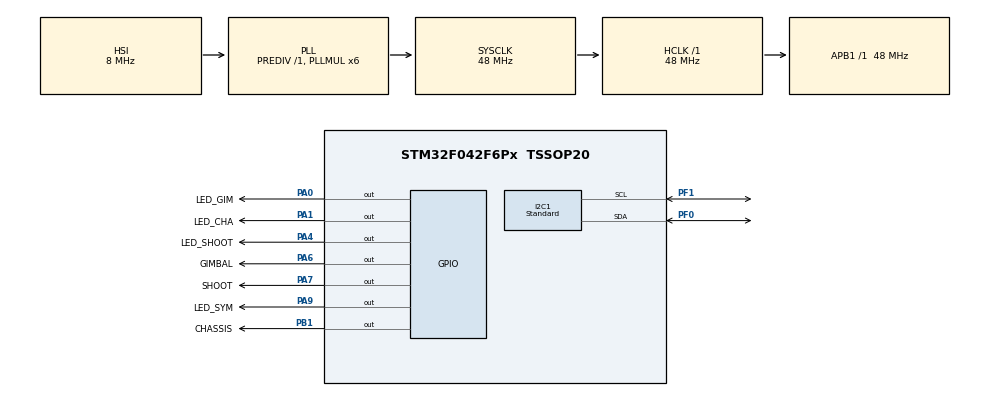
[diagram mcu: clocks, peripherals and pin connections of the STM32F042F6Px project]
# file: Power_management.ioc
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FREERTOS.Tasks01=StartTasks,0,128,StartAllTasks,Default,NULL,Dynamic,NULL,NULL
I2C1.I2C_Speed_Mode=I2C_Standard
I2C1.Timing=0x00201D2B
Mcu.Family=STM32F0
Mcu.Name=STM32F042F6Px
Mcu.Package=TSSOP20
NVIC.I2C1_IRQn=true\:3\:0\:false\:false\:true\:true\:true\:true\:true
NVIC.TIM17_IRQn=true\:3\:0\:false\:false\:true\:false\:false\:true\:true
NVIC.TimeBase=TIM17_IRQn
NVIC.TimeBaseIP=TIM17
PA0.GPIO_Label=LED_GIM
PA0.GPIO_PuPd=GPIO_NOPULL
PA0.PinState=GPIO_PIN_SET
PA0.Signal=GPIO_Output
PA1.GPIO_Label=LED_CHA
PA1.GPIO_PuPd=GPIO_NOPULL
PA1.PinState=GPIO_PIN_SET
PA1.Signal=GPIO_Output
PA13.Mode=Serial_Wire
PA13.Signal=SYS_SWDIO
PA14.Mode=Serial_Wire
PA14.Signal=SYS_SWCLK
PA4.GPIO_Label=LED_SHOOT
PA4.GPIO_PuPd=GPIO_NOPULL
PA4.PinState=GPIO_PIN_SET
PA4.Signal=GPIO_Output
PA6.GPIO_Label=GIMBAL
PA6.PinState=GPIO_PIN_RESET
PA6.Signal=GPIO_Output
PA7.GPIO_Label=SHOOT
PA7.PinState=GPIO_PIN_RESET
PA7.Signal=GPIO_Output
PA9.GPIO_Label=LED_SYM
PA9.GPIO_PuPd=GPIO_NOPULL
PA9.PinState=GPIO_PIN_SET
PA9.Signal=GPIO_Output
PB1.GPIO_Label=CHASSIS
PB1.PinState=GPIO_PIN_RESET
PB1.Signal=GPIO_Output
PF0-OSC_IN.Mode=I2C
PF0-OSC_IN.Signal=I2C1_SDA
PF1-OSC_OUT.Mode=I2C
PF1-OSC_OUT.Signal=I2C1_SCL
ProjectManager.HeapSize=0x200
ProjectManager.StackSize=0x400
ProjectManager.TargetToolchain=MDK-ARM V5.32
RCC.AHBFreq_Value=48000000
RCC.APB1Freq_Value=48000000
RCC.APB1TimFreq_Value=48000000
RCC.HCLKFreq_Value=48000000
RCC.PLLMUL=RCC_PLL_MUL6
RCC.SYSCLKFreq_VALUE=48000000
RCC.SYSCLKSource=RCC_SYSCLKSOURCE_PLLCLK
VP_FREERTOS_VS_CMSIS_V1.Mode=CMSIS_V1
VP_SYS_VS_tim17.Mode=TIM17
board=custom

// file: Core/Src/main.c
/* USER CODE BEGIN Header */
/**
  ******************************************************************************
  * @file           : main.c
  * @brief          : Main program body
  ******************************************************************************
  * @attention
  *
  * Copyright (c) 2025 STMicroelectronics.
  * All rights reserved.
  *
  * This software is licensed under terms that can be found in the LICENSE file
  * in the root directory of this software component.
  * If no LICENSE file comes with this software, it is provided AS-IS.
  *
  ******************************************************************************
  */
/* USER CODE END Header */
#include "main.h"
#include "cmsis_os.h"
#include "i2c.h"
#include "gpio.h"

/* USER CODE BEGIN Includes */
#include "INA226.h"
/* USER CODE END Includes */

void SystemClock_Config(void);
void MX_FREERTOS_Init(void);

int main(void)
{

  /* MCU Configuration--------------------------------------------------------*/

  /* Reset of all peripherals, Initializes the Flash interface and the Systick. */
  HAL_Init();

  /* Configure the system clock */
  SystemClock_Config();

  /* Initialize all configured peripherals */
  MX_GPIO_Init();
  MX_I2C1_Init();

  /* Call init function for freertos objects (in cmsis_os2.c) */
  MX_FREERTOS_Init();

  /* Start scheduler */
  osKernelStart();

  /* We should never get here as control is now taken by the scheduler */

  /* Infinite loop */
  while (1)
  {

  }
}

void SystemClock_Config(void)
{
  RCC_OscInitTypeDef RCC_OscInitStruct = {0};
  RCC_ClkInitTypeDef RCC_ClkInitStruct = {0};
  RCC_PeriphCLKInitTypeDef PeriphClkInit = {0};

  /** Initializes the RCC Oscillators according to the specified parameters
  * in the RCC_OscInitTypeDef structure.
  */
  RCC_OscInitStruct.OscillatorType = RCC_OSCILLATORTYPE_HSI;
  RCC_OscInitStruct.HSIState = RCC_HSI_ON;
  RCC_OscInitStruct.HSICalibrationValue = RCC_HSICALIBRATION_DEFAULT;
  RCC_OscInitStruct.PLL.PLLState = RCC_PLL_ON;
  RCC_OscInitStruct.PLL.PLLSource = RCC_PLLSOURCE_HSI;
  RCC_OscInitStruct.PLL.PLLMUL = RCC_PLL_MUL6;
  RCC_OscInitStruct.PLL.PREDIV = RCC_PREDIV_DIV1;
  if (HAL_RCC_OscConfig(&RCC_OscInitStruct) != HAL_OK)
  {
    Error_Handler();
  }

  /** Initializes the CPU, AHB and APB buses clocks
  */
  RCC_ClkInitStruct.ClockType = RCC_CLOCKTYPE_HCLK|RCC_CLOCKTYPE_SYSCLK
                              |RCC_CLOCKTYPE_PCLK1;
  RCC_ClkInitStruct.SYSCLKSource = RCC_SYSCLKSOURCE_PLLCLK;
  RCC_ClkInitStruct.AHBCLKDivider = RCC_SYSCLK_DIV1;
  RCC_ClkInitStruct.APB1CLKDivider = RCC_HCLK_DIV1;

  if (HAL_RCC_ClockConfig(&RCC_ClkInitStruct, FLASH_LATENCY_1) != HAL_OK)
  {
    Error_Handler();
  }
  PeriphClkInit.PeriphClockSelection = RCC_PERIPHCLK_I2C1;
  PeriphClkInit.I2c1ClockSelection = RCC_I2C1CLKSOURCE_HSI;
  if (HAL_RCCEx_PeriphCLKConfig(&PeriphClkInit) != HAL_OK)
  {
    Error_Handler();
  }
}

void HAL_TIM_PeriodElapsedCallback(TIM_HandleTypeDef *htim)
{
  if (htim->Instance == TIM17)
  {
    HAL_IncTick();
  }
}

void Error_Handler(void)
{
  __disable_irq();
  while (1)
  {
  }
}

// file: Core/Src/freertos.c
/* USER CODE BEGIN Header */
/**
  ******************************************************************************
  * File Name          : freertos.c
  * Description        : Code for freertos applications
  ******************************************************************************
  * @attention
  *
  * Copyright (c) 2025 STMicroelectronics.
  * All rights reserved.
  *
  * This software is licensed under terms that can be found in the LICENSE file
  * in the root directory of this software component.
  * If no LICENSE file comes with this software, it is provided AS-IS.
  *
  ******************************************************************************
  */
/* USER CODE END Header */

#include "FreeRTOS.h"
#include "task.h"
#include "main.h"
#include "cmsis_os.h"

/* USER CODE BEGIN Includes */
#include "UserTasks.h"
/* USER CODE END Includes */

/* USER CODE BEGIN Variables */
osThreadId ADCTaskHandle;
osThreadId LEDTaskHandle;
osThreadId PowerTaskHandle;
/* USER CODE END Variables */
osThreadId StartTasksHandle;

void StartAllTasks(void const * argument);

void MX_FREERTOS_Init(void); /* (MISRA C 2004 rule 8.1) */

/* GetIdleTaskMemory prototype (linked to static allocation support) */
void vApplicationGetIdleTaskMemory( StaticTask_t **ppxIdleTaskTCBBuffer, StackType_t **ppxIdleTaskStackBuffer, uint32_t *pulIdleTaskStackSize );

/* USER CODE BEGIN GET_IDLE_TASK_MEMORY */
static StaticTask_t xIdleTaskTCBBuffer;
static StackType_t xIdleStack[configMINIMAL_STACK_SIZE];

void vApplicationGetIdleTaskMemory( StaticTask_t **ppxIdleTaskTCBBuffer, StackType_t **ppxIdleTaskStackBuffer, uint32_t *pulIdleTaskStackSize )
{
  *ppxIdleTaskTCBBuffer = &xIdleTaskTCBBuffer;
  *ppxIdleTaskStackBuffer = &xIdleStack[0];
  *pulIdleTaskStackSize = configMINIMAL_STACK_SIZE;
  /* place for user code */
}
/* USER CODE END GET_IDLE_TASK_MEMORY */

void MX_FREERTOS_Init(void) {

  /* Create the thread(s) */
  /* definition and creation of StartTasks */
  osThreadDef(StartTasks, StartAllTasks, osPriorityNormal, 0, 128);
  StartTasksHandle = osThreadCreate(osThread(StartTasks), NULL);

  /* USER CODE BEGIN RTOS_THREADS */
  osThreadDef(ADCTask, ADC_Task, osPriorityNormal, 0, 256);
  ADCTaskHandle = osThreadCreate(osThread(ADCTask), NULL);
  osThreadDef(LEDTask, LED_Task, osPriorityNormal, 0, 128);
  LEDTaskHandle = osThreadCreate(osThread(LEDTask), NULL);
  osThreadDef(PowerTask, Power_Task, osPriorityNormal, 0, 128);
  PowerTaskHandle = osThreadCreate(osThread(PowerTask), NULL);
  /* USER CODE END RTOS_THREADS */

}

void StartAllTasks(void const * argument)
{
  /* USER CODE BEGIN StartAllTasks */
  vTaskDelete(NULL);
  /* USER CODE END StartAllTasks */
}
